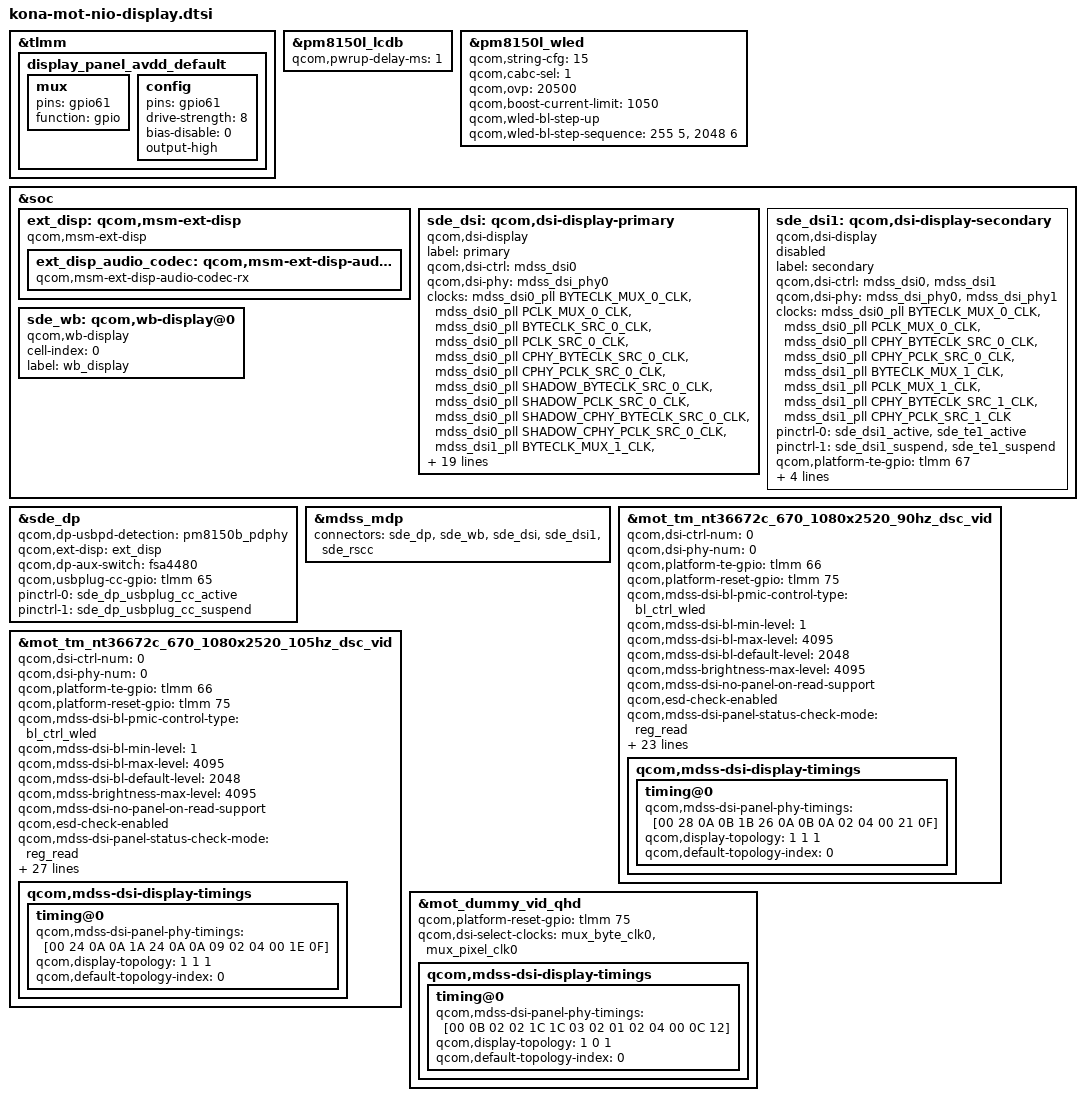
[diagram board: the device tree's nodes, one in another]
#include <dt-bindings/clock/mdss-7nm-pll-clk.h>
#include "dsi-panel-mot-tianma-nt36672c-670-1080x2520-90hz-dsc-video.dtsi"
#include "dsi-panel-mot-tianma-nt36672c-670-1080x2520-105hz-dsc-video.dtsi"
#include "dsi-panel-mot-dummy-qhd-video.dtsi"

&tlmm {
	display_panel_avdd_default: display_panel_avdd_default {
		mux {
			pins = "gpio61";
			function = "gpio";
		};

		config {
			pins = "gpio61";
			drive-strength = <8>;
			bias-disable = <0>;
			output-high;
		};
	};
};


&pm8150l_lcdb {
    status = "ok";
    qcom,pwrup-delay-ms = <1>;
};

&pm8150l_wled {
	qcom,string-cfg = <15>;
	qcom,cabc-sel = <1>;
	qcom,ovp = <20500>;
	qcom,boost-current-limit = <1050>;

	qcom,wled-bl-step-up;
	qcom,wled-bl-step-sequence = <255 5>, <2048 6>;

	status = "ok";

	/delete-node/ wled_switch;
};

&sde_dsi1 {
	status = "disabled";
};

&soc {
	ext_disp: qcom,msm-ext-disp {
		compatible = "qcom,msm-ext-disp";

		ext_disp_audio_codec: qcom,msm-ext-disp-audio-codec-rx {
			compatible = "qcom,msm-ext-disp-audio-codec-rx";
		};
	};

	sde_dsi: qcom,dsi-display-primary {
		compatible = "qcom,dsi-display";
		label = "primary";

		qcom,dsi-ctrl = <&mdss_dsi0>;
		qcom,dsi-phy = <&mdss_dsi_phy0>;

		clocks = <&mdss_dsi0_pll BYTECLK_MUX_0_CLK>,
			 <&mdss_dsi0_pll PCLK_MUX_0_CLK>,
			 <&mdss_dsi0_pll BYTECLK_SRC_0_CLK>,
			 <&mdss_dsi0_pll PCLK_SRC_0_CLK>,
			 <&mdss_dsi0_pll CPHY_BYTECLK_SRC_0_CLK>,
			 <&mdss_dsi0_pll CPHY_PCLK_SRC_0_CLK>,
			 <&mdss_dsi0_pll SHADOW_BYTECLK_SRC_0_CLK>,
			 <&mdss_dsi0_pll SHADOW_PCLK_SRC_0_CLK>,
			 <&mdss_dsi0_pll SHADOW_CPHY_BYTECLK_SRC_0_CLK>,
			 <&mdss_dsi0_pll SHADOW_CPHY_PCLK_SRC_0_CLK>,
			 <&mdss_dsi1_pll BYTECLK_MUX_1_CLK>,
			 <&mdss_dsi1_pll PCLK_MUX_1_CLK>,
			 <&mdss_dsi1_pll BYTECLK_SRC_1_CLK>,
			 <&mdss_dsi1_pll PCLK_SRC_1_CLK>,
			 <&mdss_dsi1_pll CPHY_BYTECLK_SRC_1_CLK>,
			 <&mdss_dsi1_pll CPHY_PCLK_SRC_1_CLK>,
			 <&mdss_dsi1_pll SHADOW_BYTECLK_SRC_1_CLK>,
			 <&mdss_dsi1_pll SHADOW_PCLK_SRC_1_CLK>,
			 <&mdss_dsi1_pll SHADOW_CPHY_BYTECLK_SRC_1_CLK>,
			 <&mdss_dsi1_pll SHADOW_CPHY_PCLK_SRC_1_CLK>;

		clock-names = "mux_byte_clk0", "mux_pixel_clk0",
				"src_byte_clk0", "src_pixel_clk0",
				"cphy_byte_clk0", "cphy_pixel_clk0",
				"shadow_byte_clk0", "shadow_pixel_clk0",
				"shadow_cphybyte_clk0", "shadow_cphypixel_clk0",
				"mux_byte_clk1", "mux_pixel_clk1",
				"src_byte_clk1", "src_pixel_clk1",
				"cphy_byte_clk1", "cphy_pixel_clk1",
				"shadow_byte_clk1", "shadow_pixel_clk1",
				"shadow_cphybyte_clk1", "shadow_cphypixel_clk1";

		pinctrl-names = "panel_active", "panel_suspend";
		pinctrl-0 = <&sde_dsi_active &sde_te_active>;
		pinctrl-1 = <&sde_dsi_suspend &sde_te_suspend>;

		qcom,platform-te-gpio = <&tlmm 66 0>;
		qcom,panel-te-source = <0>;

		vddio_disp-supply = <&pm8150a_l1>;
		vsp_disp-supply = <&lcdb_ldo_vreg>;
		vsn_disp-supply = <&lcdb_ncp_vreg>;

		qcom,mdp = <&mdss_mdp>;
		qcom,dsi-default-panel = <&mot_tm_nt36672c_670_1080x2520_90hz_dsc_vid>;
	};

	sde_dsi1: qcom,dsi-display-secondary {
		compatible = "qcom,dsi-display";
		label = "secondary";

		qcom,dsi-ctrl = <&mdss_dsi0 &mdss_dsi1>;
		qcom,dsi-phy = <&mdss_dsi_phy0 &mdss_dsi_phy1>;

		clocks = <&mdss_dsi0_pll BYTECLK_MUX_0_CLK>,
			 <&mdss_dsi0_pll PCLK_MUX_0_CLK>,
			 <&mdss_dsi0_pll CPHY_BYTECLK_SRC_0_CLK>,
			 <&mdss_dsi0_pll CPHY_PCLK_SRC_0_CLK>,
			 <&mdss_dsi1_pll BYTECLK_MUX_1_CLK>,
			 <&mdss_dsi1_pll PCLK_MUX_1_CLK>,
			 <&mdss_dsi1_pll CPHY_BYTECLK_SRC_1_CLK>,
			 <&mdss_dsi1_pll CPHY_PCLK_SRC_1_CLK>;
		clock-names = "mux_byte_clk0", "mux_pixel_clk0",
			      "cphy_byte_clk0", "cphy_pixel_clk0",
			      "mux_byte_clk1", "mux_pixel_clk1",
			      "cphy_byte_clk1", "cphy_pixel_clk1";

		pinctrl-names = "panel_active", "panel_suspend";
		pinctrl-0 = <&sde_dsi1_active &sde_te1_active>;
		pinctrl-1 = <&sde_dsi1_suspend &sde_te1_suspend>;

		qcom,platform-te-gpio = <&tlmm 67 0>;
		qcom,panel-te-source = <1>;

		vddio-supply = <&pm8150_l14>;
		vdd-supply = <&pm8150a_l11>;

		qcom,mdp = <&mdss_mdp>;
	};

	sde_wb: qcom,wb-display@0 {
		compatible = "qcom,wb-display";
		cell-index = <0>;
		label = "wb_display";
	};
};

&sde_dp {
	qcom,dp-usbpd-detection = <&pm8150b_pdphy>;
	qcom,ext-disp = <&ext_disp>;
	qcom,dp-aux-switch = <&fsa4480>;

	qcom,usbplug-cc-gpio = <&tlmm 65 0>;

	//qcom,aux-en-gpio = <&tlmm 12 0>;
	//qcom,aux-sel-gpio = <&tlmm 13 0>;
	//qcom,dp-gpio-aux-switch;

	pinctrl-names = "mdss_dp_active", "mdss_dp_sleep";
	pinctrl-0 = <&sde_dp_usbplug_cc_active>;
	pinctrl-1 = <&sde_dp_usbplug_cc_suspend>;
};

&mdss_mdp {
	connectors = <&sde_dp &sde_wb &sde_dsi &sde_dsi1 &sde_rscc>;
};

&mot_tm_nt36672c_670_1080x2520_90hz_dsc_vid {
	qcom,dsi-ctrl-num = <0>;
	qcom,dsi-phy-num = <0>;

	qcom,platform-te-gpio = <&tlmm 66 0>;
	qcom,platform-reset-gpio = <&tlmm 75 0>;

	qcom,mdss-dsi-bl-pmic-control-type = "bl_ctrl_wled";
	qcom,mdss-dsi-bl-min-level = <1>;
	qcom,mdss-dsi-bl-max-level = <4095>;
	qcom,mdss-dsi-bl-default-level = <2048>;
	qcom,mdss-brightness-max-level = <4095>;

	qcom,mdss-dsi-no-panel-on-read-support;
	qcom,esd-check-enabled;
	qcom,mdss-dsi-panel-status-check-mode = "reg_read";
	qcom,mdss-dsi-panel-status-command = [06 01 00 01 00 00 01 0A];
	qcom,mdss-dsi-panel-status-command-state = "dsi_lp_mode";
	qcom,mdss-dsi-panel-status-value = <0x9c>;
	qcom,mdss-dsi-panel-status-read-length = <1>;

	qcom,mdss-dsi-panel-hdr-enabled;
	qcom,mdss-dsi-panel-hdr-color-primaries = <14500 15500 32000
	        17000 15500 30000 8000 3000>;
	qcom,mdss-dsi-panel-peak-brightness = <4200000>;
	qcom,mdss-dsi-panel-blackness-level = <4200>;

	qcom,tp_state_check_enable;

//	qcom,mdss-dsi-pan-enable-dynamic-fps;
//	qcom,mdss-dsi-pan-fps-update = "dfps_immediate_porch_mode_vfp";
//	qcom,dsi-supported-dfps-list = <60 90>;

	qcom,mdss-dsi-hbm-on-command = [15 01 00 00 00 00 02 51 FF];
	qcom,mdss-dsi-hbm-on-command-state =  "dsi_lp_mode";
	qcom,mdss-dsi-hbm-off-command = [15 01 00 00 00 00 02 51 CC];
	qcom,mdss-dsi-hbm-off-command-state =  "dsi_lp_mode";
	qcom,mdss-dsi-hbm-type = "lcd-dcs-wled";

	qcom,dsi-select-clocks = "mux_byte_clk0", "mux_pixel_clk0";
	qcom,mdss-dsi-display-timings {
		timing@0 {
			/* Phy 4; w=1080 h=2520; 8bits 90hz; 3.75x dsc */
			qcom,mdss-dsi-panel-phy-timings = [00 28 0A 0B 1B 26 0A
					0B 0A 02 04 00 21 0F];
			qcom,display-topology = <1 1 1>;
			qcom,default-topology-index = <0>;
		};
	};
};

&mot_tm_nt36672c_670_1080x2520_105hz_dsc_vid {
	qcom,dsi-ctrl-num = <0>;
	qcom,dsi-phy-num = <0>;

	qcom,platform-te-gpio = <&tlmm 66 0>;
	qcom,platform-reset-gpio = <&tlmm 75 0>;

	qcom,mdss-dsi-bl-pmic-control-type = "bl_ctrl_wled";
	qcom,mdss-dsi-bl-min-level = <1>;
	qcom,mdss-dsi-bl-max-level = <4095>;
	qcom,mdss-dsi-bl-default-level = <2048>;
	qcom,mdss-brightness-max-level = <4095>;

	qcom,mdss-dsi-no-panel-on-read-support;
	qcom,esd-check-enabled;
	qcom,mdss-dsi-panel-status-check-mode = "reg_read";
	qcom,mdss-dsi-panel-status-command = [06 01 00 01 00 00 01 0A];
	qcom,mdss-dsi-panel-status-command-state = "dsi_lp_mode";
	qcom,mdss-dsi-panel-status-value = <0x9c>;
	qcom,mdss-dsi-panel-status-read-length = <1>;

	qcom,mdss-dsi-panel-hdr-enabled;
	qcom,mdss-dsi-panel-hdr-color-primaries = <14500 15500 32000
	        17000 15500 30000 8000 3000>;
	qcom,mdss-dsi-panel-peak-brightness = <4200000>;
	qcom,mdss-dsi-panel-blackness-level = <4200>;

	qcom,tp_state_check_enable;

	qcom,mdss-dsi-pan-enable-dynamic-fps;
	qcom,mdss-dsi-pan-fps-update = "dfps_immediate_porch_mode_vfp";
	qcom,dsi-supported-dfps-list = <60 105>;

	qcom,mdss-dsi-hbm-on-command = [15 01 00 00 00 00 02 51 FF];
	qcom,mdss-dsi-hbm-on-command-state =  "dsi_lp_mode";
	qcom,mdss-dsi-hbm-off-command = [15 01 00 00 00 00 02 51 CC];
	qcom,mdss-dsi-hbm-off-command-state =  "dsi_lp_mode";
	qcom,mdss-dsi-hbm-type = "lcd-dcs-wled";

	qcom,dsi-select-clocks = "mux_byte_clk0", "mux_pixel_clk0";
	qcom,mdss-dsi-display-timings {
		timing@0 {
			/* Phy 4; w=1080 h=2520; 8bits 90hz; 3.75x dsc */
			qcom,mdss-dsi-panel-phy-timings = [00 24 0A 0A 1A 24 0A
					0A 09 02 04 00 1E 0F];
			qcom,display-topology = <1 1 1>;
			qcom,default-topology-index = <0>;
		};
	};
};

&mot_dummy_vid_qhd {
	qcom,platform-reset-gpio = <&tlmm 75 0>;

	qcom,dsi-select-clocks = "mux_byte_clk0", "mux_pixel_clk0";
	qcom,mdss-dsi-display-timings {
		timing@0 {
			qcom,mdss-dsi-panel-phy-timings = [00 0B 02 02 1C 1C 03
							02 01 02 04 00 0C 12];
			qcom,display-topology = <1 0 1>;
			qcom,default-topology-index = <0>;
		};
	};
};
